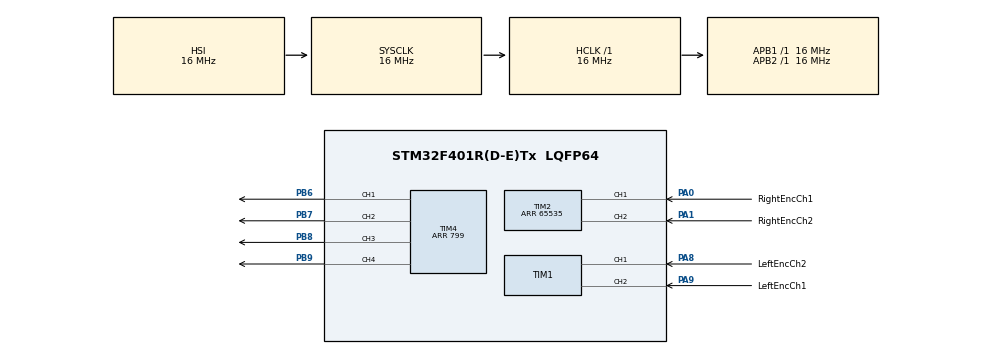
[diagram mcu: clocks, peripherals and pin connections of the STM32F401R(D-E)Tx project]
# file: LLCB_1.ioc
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Mcu.Family=STM32F4
Mcu.Name=STM32F401R(D-E)Tx
Mcu.Package=LQFP64
NVIC.PriorityGroup=NVIC_PRIORITYGROUP_4
NVIC.TIM4_IRQn=true\:0\:0\:false\:false\:true\:true\:true\:true
PA0-WKUP.GPIO_Label=RightEncCh1
PA0-WKUP.Signal=S_TIM2_CH1_ETR
PA1.GPIO_Label=RightEncCh2
PA1.Signal=S_TIM2_CH2
PA8.GPIO_Label=LeftEncCh2
PA8.Signal=S_TIM1_CH1
PA9.GPIO_Label=LeftEncCh1
PA9.Signal=S_TIM1_CH2
PB6.Signal=S_TIM4_CH1
PB7.Signal=S_TIM4_CH2
PB8.Signal=S_TIM4_CH3
PB9.Signal=S_TIM4_CH4
ProjectManager.HeapSize=0x200
ProjectManager.StackSize=0x400
ProjectManager.TargetToolchain=STM32CubeIDE
RCC.AHBFreq_Value=16000000
RCC.APB1Freq_Value=16000000
RCC.APB2Freq_Value=16000000
RCC.CortexFreq_Value=16000000
RCC.HSE_VALUE=25000000
RCC.HSI_VALUE=16000000
RCC.LSE_VALUE=32768
RCC.SYSCLKFreq_VALUE=16000000
RCC.VCOOutputFreq_Value=192000000
SH.S_TIM1_CH1.0=TIM1_CH1,Encoder_Interface
SH.S_TIM1_CH2.0=TIM1_CH2,Encoder_Interface
SH.S_TIM2_CH1_ETR.0=TIM2_CH1,Encoder_Interface
SH.S_TIM2_CH2.0=TIM2_CH2,Encoder_Interface
SH.S_TIM4_CH1.0=TIM4_CH1,PWM Generation1 CH1
SH.S_TIM4_CH2.0=TIM4_CH2,PWM Generation2 CH2
SH.S_TIM4_CH3.0=TIM4_CH3,PWM Generation3 CH3
SH.S_TIM4_CH4.0=TIM4_CH4,PWM Generation4 CH4
TIM1.EncoderMode=TIM_ENCODERMODE_TI12
TIM2.EncoderMode=TIM_ENCODERMODE_TI12
TIM2.IC1Filter=5
TIM2.IC2Filter=5
TIM2.Period=65535
TIM4.Channel-PWM\ Generation1\ CH1=TIM_CHANNEL_1
TIM4.Channel-PWM\ Generation2\ CH2=TIM_CHANNEL_2
TIM4.Channel-PWM\ Generation3\ CH3=TIM_CHANNEL_3
TIM4.Channel-PWM\ Generation4\ CH4=TIM_CHANNEL_4
TIM4.Period=799
board=custom

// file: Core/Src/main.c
/* USER CODE BEGIN Header */
/**
  ******************************************************************************
  * @file           : main.c
  * @brief          : Main program body
  ******************************************************************************
  * @attention
  *
  * Copyright (c) 2026 STMicroelectronics.
  * All rights reserved.
  *
  * This software is licensed under terms that can be found in the LICENSE file
  * in the root directory of this software component.
  * If no LICENSE file comes with this software, it is provided AS-IS.
  *
  ******************************************************************************
  */
/* USER CODE END Header */
#include "main.h"

/* USER CODE BEGIN Includes */
#include "encoders.h"
/* USER CODE END Includes */

TIM_HandleTypeDef htim1;
TIM_HandleTypeDef htim2;
TIM_HandleTypeDef htim4;

/* USER CODE BEGIN PV */
int16_t left_counts = 0;
int16_t right_counts = 0;
/* USER CODE END PV */

void SystemClock_Config(void);
static void MX_GPIO_Init(void);
static void MX_TIM1_Init(void);
static void MX_TIM2_Init(void);
static void MX_TIM4_Init(void);

int main(void)
{

  /* MCU Configuration--------------------------------------------------------*/

  /* Reset of all peripherals, Initializes the Flash interface and the Systick. */
  HAL_Init();

  /* Configure the system clock */
  SystemClock_Config();

  /* Initialize all configured peripherals */
  MX_GPIO_Init();
  MX_TIM1_Init();
  MX_TIM2_Init();
  MX_TIM4_Init();
  /* USER CODE BEGIN 2 */
  HAL_TIM_Encoder_Start(&htim1, TIM_CHANNEL_ALL);
  HAL_TIM_Encoder_Start(&htim2, TIM_CHANNEL_ALL);
  /* USER CODE END 2 */

  /* Infinite loop */
  /* USER CODE BEGIN WHILE */
  while (1)
  {
	  left_counts = getLeftEncoderCount();
	  right_counts = getRightEncoderCount();
    /* USER CODE END WHILE */

  }
}

void SystemClock_Config(void)
{
  RCC_OscInitTypeDef RCC_OscInitStruct = {0};
  RCC_ClkInitTypeDef RCC_ClkInitStruct = {0};

  /** Configure the main internal regulator output voltage
  */
  __HAL_RCC_PWR_CLK_ENABLE();
  __HAL_PWR_VOLTAGESCALING_CONFIG(PWR_REGULATOR_VOLTAGE_SCALE2);

  /** Initializes the RCC Oscillators according to the specified parameters
  * in the RCC_OscInitTypeDef structure.
  */
  RCC_OscInitStruct.OscillatorType = RCC_OSCILLATORTYPE_HSI;
  RCC_OscInitStruct.HSIState = RCC_HSI_ON;
  RCC_OscInitStruct.HSICalibrationValue = RCC_HSICALIBRATION_DEFAULT;
  RCC_OscInitStruct.PLL.PLLState = RCC_PLL_NONE;
  if (HAL_RCC_OscConfig(&RCC_OscInitStruct) != HAL_OK)
  {
    Error_Handler();
  }

  /** Initializes the CPU, AHB and APB buses clocks
  */
  RCC_ClkInitStruct.ClockType = RCC_CLOCKTYPE_HCLK|RCC_CLOCKTYPE_SYSCLK
                              |RCC_CLOCKTYPE_PCLK1|RCC_CLOCKTYPE_PCLK2;
  RCC_ClkInitStruct.SYSCLKSource = RCC_SYSCLKSOURCE_HSI;
  RCC_ClkInitStruct.AHBCLKDivider = RCC_SYSCLK_DIV1;
  RCC_ClkInitStruct.APB1CLKDivider = RCC_HCLK_DIV1;
  RCC_ClkInitStruct.APB2CLKDivider = RCC_HCLK_DIV1;

  if (HAL_RCC_ClockConfig(&RCC_ClkInitStruct, FLASH_LATENCY_0) != HAL_OK)
  {
    Error_Handler();
  }
}

static void MX_TIM1_Init(void)
{

  TIM_Encoder_InitTypeDef sConfig = {0};
  TIM_MasterConfigTypeDef sMasterConfig = {0};

  htim1.Instance = TIM1;
  htim1.Init.Prescaler = 0;
  htim1.Init.CounterMode = TIM_COUNTERMODE_UP;
  htim1.Init.Period = 65535;
  htim1.Init.ClockDivision = TIM_CLOCKDIVISION_DIV1;
  htim1.Init.RepetitionCounter = 0;
  htim1.Init.AutoReloadPreload = TIM_AUTORELOAD_PRELOAD_DISABLE;
  sConfig.EncoderMode = TIM_ENCODERMODE_TI12;
  sConfig.IC1Polarity = TIM_ICPOLARITY_RISING;
  sConfig.IC1Selection = TIM_ICSELECTION_DIRECTTI;
  sConfig.IC1Prescaler = TIM_ICPSC_DIV1;
  sConfig.IC1Filter = 0;
  sConfig.IC2Polarity = TIM_ICPOLARITY_RISING;
  sConfig.IC2Selection = TIM_ICSELECTION_DIRECTTI;
  sConfig.IC2Prescaler = TIM_ICPSC_DIV1;
  sConfig.IC2Filter = 0;
  if (HAL_TIM_Encoder_Init(&htim1, &sConfig) != HAL_OK)
  {
    Error_Handler();
  }
  sMasterConfig.MasterOutputTrigger = TIM_TRGO_RESET;
  sMasterConfig.MasterSlaveMode = TIM_MASTERSLAVEMODE_DISABLE;
  if (HAL_TIMEx_MasterConfigSynchronization(&htim1, &sMasterConfig) != HAL_OK)
  {
    Error_Handler();
  }

}

static void MX_TIM2_Init(void)
{

  TIM_Encoder_InitTypeDef sConfig = {0};
  TIM_MasterConfigTypeDef sMasterConfig = {0};

  htim2.Instance = TIM2;
  htim2.Init.Prescaler = 0;
  htim2.Init.CounterMode = TIM_COUNTERMODE_UP;
  htim2.Init.Period = 65535;
  htim2.Init.ClockDivision = TIM_CLOCKDIVISION_DIV1;
  htim2.Init.AutoReloadPreload = TIM_AUTORELOAD_PRELOAD_DISABLE;
  sConfig.EncoderMode = TIM_ENCODERMODE_TI12;
  sConfig.IC1Polarity = TIM_ICPOLARITY_RISING;
  sConfig.IC1Selection = TIM_ICSELECTION_DIRECTTI;
  sConfig.IC1Prescaler = TIM_ICPSC_DIV1;
  sConfig.IC1Filter = 5;
  sConfig.IC2Polarity = TIM_ICPOLARITY_RISING;
  sConfig.IC2Selection = TIM_ICSELECTION_DIRECTTI;
  sConfig.IC2Prescaler = TIM_ICPSC_DIV1;
  sConfig.IC2Filter = 5;
  if (HAL_TIM_Encoder_Init(&htim2, &sConfig) != HAL_OK)
  {
    Error_Handler();
  }
  sMasterConfig.MasterOutputTrigger = TIM_TRGO_RESET;
  sMasterConfig.MasterSlaveMode = TIM_MASTERSLAVEMODE_DISABLE;
  if (HAL_TIMEx_MasterConfigSynchronization(&htim2, &sMasterConfig) != HAL_OK)
  {
    Error_Handler();
  }

}

static void MX_TIM4_Init(void)
{

  TIM_MasterConfigTypeDef sMasterConfig = {0};
  TIM_OC_InitTypeDef sConfigOC = {0};

  htim4.Instance = TIM4;
  htim4.Init.Prescaler = 0;
  htim4.Init.CounterMode = TIM_COUNTERMODE_UP;
  htim4.Init.Period = 799;
  htim4.Init.ClockDivision = TIM_CLOCKDIVISION_DIV1;
  htim4.Init.AutoReloadPreload = TIM_AUTORELOAD_PRELOAD_DISABLE;
  if (HAL_TIM_PWM_Init(&htim4) != HAL_OK)
  {
    Error_Handler();
  }
  sMasterConfig.MasterOutputTrigger = TIM_TRGO_RESET;
  sMasterConfig.MasterSlaveMode = TIM_MASTERSLAVEMODE_DISABLE;
  if (HAL_TIMEx_MasterConfigSynchronization(&htim4, &sMasterConfig) != HAL_OK)
  {
    Error_Handler();
  }
  sConfigOC.OCMode = TIM_OCMODE_PWM1;
  sConfigOC.Pulse = 0;
  sConfigOC.OCPolarity = TIM_OCPOLARITY_HIGH;
  sConfigOC.OCFastMode = TIM_OCFAST_DISABLE;
  if (HAL_TIM_PWM_ConfigChannel(&htim4, &sConfigOC, TIM_CHANNEL_1) != HAL_OK)
  {
    Error_Handler();
  }
  if (HAL_TIM_PWM_ConfigChannel(&htim4, &sConfigOC, TIM_CHANNEL_2) != HAL_OK)
  {
    Error_Handler();
  }
  if (HAL_TIM_PWM_ConfigChannel(&htim4, &sConfigOC, TIM_CHANNEL_3) != HAL_OK)
  {
    Error_Handler();
  }
  if (HAL_TIM_PWM_ConfigChannel(&htim4, &sConfigOC, TIM_CHANNEL_4) != HAL_OK)
  {
    Error_Handler();
  }
  HAL_TIM_MspPostInit(&htim4);

}

static void MX_GPIO_Init(void)
{

  /* GPIO Ports Clock Enable */
  __HAL_RCC_GPIOA_CLK_ENABLE();
  __HAL_RCC_GPIOB_CLK_ENABLE();

}

void Error_Handler(void)
{
  __disable_irq();
  while (1)
  {
  }
}
